# STM32G431RB register map
Vendor: STMicroelectronics
CPU: CM4
Registers are 32-bit, access not given, reset 0x0 unless marked. A register's access mark holds for its fields unless they carry their own. Offsets are from the block's base; lines under a group give offsets from that group; [hi:lo] are bit positions; {n}, {i} and the like mark numbered series; 'fields as' and 'values as' point back to an identical list; <NAME> marks a mode.

## Memory map
0x40000000 TIM2 — General purpose timer
0x40013800 USART1 — Universal synchronous/asynchronous receiver/transmitter
0x40021000 RCC — Reset and clock control
0x48000000 GPIOA — General purpose I/O A

## RCC — Reset and clock control
Base 0x40021000
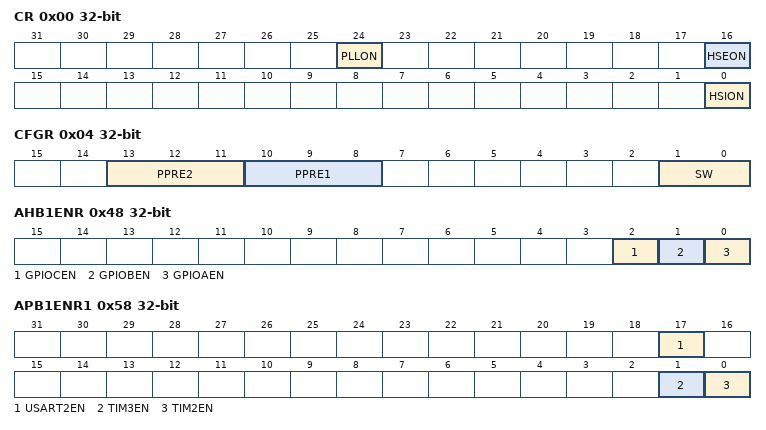
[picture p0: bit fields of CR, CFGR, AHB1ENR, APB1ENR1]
0x00 CR — Clock control
  [24] PLLON, [16] HSEON, [0] HSION
0x04 CFGR — Clock configuration
  [13:11] PPRE2, [10:8] PPRE1, [1:0] SW
0x48 AHB1ENR — AHB1 peripheral clock enable
  [2] GPIOCEN, [1] GPIOBEN, [0] GPIOAEN
0x58 APB1ENR1 — APB1 peripheral clock enable 1
  [17] USART2EN, [1] TIM3EN, [0] TIM2EN
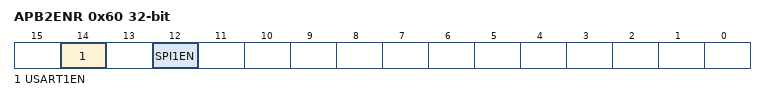
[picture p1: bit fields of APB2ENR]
0x60 APB2ENR — APB2 peripheral clock enable
  [14] USART1EN, [12] SPI1EN

## GPIOA — General purpose I/O A
Base 0x48000000
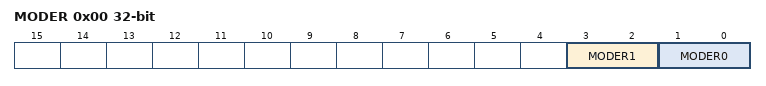
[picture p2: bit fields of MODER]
0x00 MODER — Mode
  [3:2] MODER1, [1:0] MODER0
0x10 IDR — Input data
0x14 ODR — Output data
0x18 BSRR — Bit set/reset

## USART1 — Universal synchronous/asynchronous receiver/transmitter
Base 0x40013800
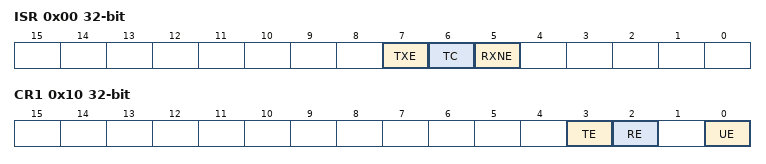
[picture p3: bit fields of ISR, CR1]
0x00 ISR — Interrupt status
  [7] TXE, [6] TC, [5] RXNE
0x0C BRR — Baud rate
0x10 CR1 — Control 1
  [3] TE, [2] RE, [0] UE
0x24 RDR — Receive data
0x28 TDR — Transmit data

## TIM2 — General purpose timer
Base 0x40000000
0x00 CR1 — Control 1
0x24 CNT — Counter
0x28 PSC — Prescaler
0x2C ARR — Auto-reload
